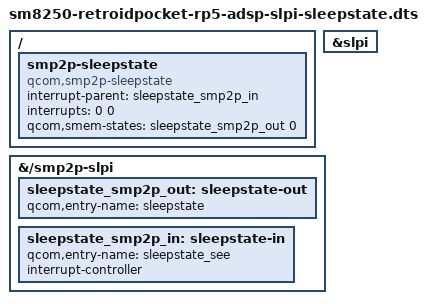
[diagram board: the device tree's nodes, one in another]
// SPDX-License-Identifier: BSD-3-Clause
/*
 * Phase 6I follow-up: Phase 6D product baseline with ADSP registered offline,
 * SLPI running, and the exact stock DSPS/SLPI SMP2P sleep-state handshake.
 */

#include "sm8250-retroidpocket-rp5-reenable-display-gpu-gamepad-active-only-ufs-wireless-usb-typec-dp-adsp.dts"

&slpi {
	status = "okay";
};

&{/smp2p-slpi} {
	sleepstate_smp2p_out: sleepstate-out {
		qcom,entry-name = "sleepstate";
		#qcom,smem-state-cells = <1>;
	};

	sleepstate_smp2p_in: sleepstate-in {
		qcom,entry-name = "sleepstate_see";
		interrupt-controller;
		#interrupt-cells = <2>;
	};
};

/ {
	smp2p-sleepstate {
		compatible = "qcom,smp2p-sleepstate";
		interrupt-parent = <&sleepstate_smp2p_in>;
		interrupts = <0 0>;
		interrupt-names = "smp2p-sleepstate-in";
		qcom,smem-states = <&sleepstate_smp2p_out 0>;
	};
};
